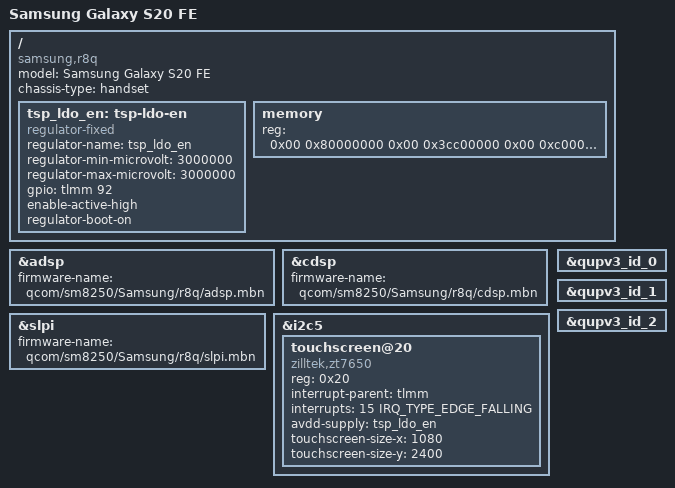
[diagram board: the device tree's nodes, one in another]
// SPDX-License-Identifier: GPL-2.0-only

/dts-v1/;

#include "sm8250-samsung-common.dtsi"

/ {
    model = "Samsung Galaxy S20 FE";
    compatible = "samsung,r8q", "qcom,sm8250";
    chassis-type = "handset";

    tsp_ldo_en: tsp-ldo-en {
        compatible = "regulator-fixed";
        regulator-name = "tsp_ldo_en";
        regulator-min-microvolt = <3000000>;
        regulator-max-microvolt = <3000000>;
        gpio = <&tlmm 92 GPIO_ACTIVE_HIGH>;
        enable-active-high;
        regulator-boot-on;
        };
memory {
        device_type = "memory";
        reg = <0x00 0x80000000 0x00 0x3cc00000 0x00 0xc0000000 0x01 0x40000000>;
    };
};

&adsp {
	firmware-name = "qcom/sm8250/Samsung/r8q/adsp.mbn";
	status = "okay";
};

&cdsp {
	firmware-name = "qcom/sm8250/Samsung/r8q/cdsp.mbn";
	status = "okay";
};

&slpi {
	firmware-name = "qcom/sm8250/Samsung/r8q/slpi.mbn";
	status = "okay";
};

&i2c5 {
    status = "okay";

    touchscreen@20 {
        compatible = "zilltek,zt7650";
        reg = <0x20>;
        interrupt-parent = <&tlmm>;
        interrupts = <15 IRQ_TYPE_EDGE_FALLING>;
        avdd-supply = <&tsp_ldo_en>;
        touchscreen-size-x = <1080>;
        touchscreen-size-y = <2400>;
        status = "okay";
    };
};

&qupv3_id_0 {
    status = "okay";
};

&qupv3_id_1 {
    status = "okay";
};

&qupv3_id_2 {
    status = "okay";
};
